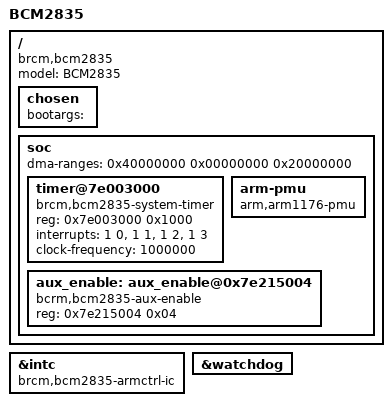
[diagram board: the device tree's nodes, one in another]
#include "bcm2708_common.dtsi"

/ {
	compatible = "brcm,bcm2835";
	model = "BCM2835";

	chosen {
		bootargs = "";
	};

	soc {
		ranges = <0x7e000000 0x20000000 0x01000000>;
		dma-ranges = <0x40000000 0x00000000 0x20000000>;

		timer@7e003000 {
			compatible = "brcm,bcm2835-system-timer";
			reg = <0x7e003000 0x1000>;
			interrupts = <1 0>, <1 1>, <1 2>, <1 3>;
			clock-frequency = <1000000>;
		};

		arm-pmu {
			compatible = "arm,arm1176-pmu";
		};

		aux_enable: aux_enable@0x7e215004 {
			compatible = "bcrm,bcm2835-aux-enable";
			reg = <0x7e215004 0x04>;
		};
	};
};

&intc {
	compatible = "brcm,bcm2835-armctrl-ic";
};

&watchdog {
	status = "okay";
};
